# USCI_B0__I2C_Mode_6 register map
Vendor: Texas Instruments
Peripheral module from a debugger description file (folder msp430).
Registers are 16-bit, read-write, reset 0x0 unless marked. A register's access mark holds for its fields unless they carry their own. Offsets are as the file gives them; lines under a group give offsets from that group; [hi:lo] are bit positions; {n}, {i} and the like mark numbered series; 'fields as' and 'values as' point back to an identical list; <NAME> marks a mode.

## USCI_B0_I2C_Mode
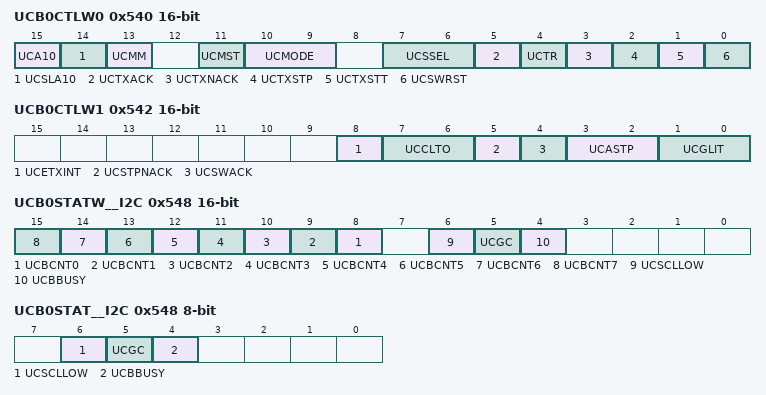
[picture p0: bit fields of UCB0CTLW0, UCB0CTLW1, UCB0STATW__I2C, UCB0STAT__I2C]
0x540 UCB0CTLW0 — USCI B0 Control Word Register 0
  [15] UCA10 — 10-bit Address Mode
  [14] UCSLA10 — 10-bit Slave Address Mode
  [13] UCMM — Multi-Master Environment
  [11] UCMST — Sync. Mode: Master Select
  [10:9] UCMODE — Sync. Mode: USCI Mode 1
    {v}=Sync. Mode: USCI Mode: {v} (v=0..3)
  [7:6] UCSSEL — USCI 1 Clock Source Select 1
    {v}=USCI 0 Clock Source: {v} (v=0..3)
  [5] UCTXACK — Transmit ACK
  [4] UCTR — Transmit/Receive Select/Flag
  [3] UCTXNACK — Transmit NACK
  [2] UCTXSTP — Transmit STOP
  [1] UCTXSTT — Transmit START
  [0] UCSWRST — USCI Software Reset
0x540 UCB0CTL1 8-bit access not given reset not defined — USCI B0 Control Register 1
0x541 UCB0CTL0 8-bit access not given reset not defined — USCI B0 Control Register 0
0x542 UCB0CTLW1 — USCI B0 Control Word Register 1
  [8] UCETXINT — USCI Early UCTXIFG0
  [7:6] UCCLTO — USCI Clock low timeout Bit: 1
    {v}=USCI Clock low timeout: {v} (v=0..3)
  [5] UCSTPNACK — USCI Acknowledge Stop last byte
  [4] UCSWACK — USCI Software controlled ACK
  [3:2] UCASTP — USCI Automatic Stop condition generation Bit: 1
    {v}=USCI Automatic Stop condition generation: {v} (v=0..3)
  [1:0] UCGLIT — USCI Deglitch time Bit: 1
    {v}=USCI Deglitch time: {v} (v=0..3)
0x546 UCB0BRW access not given reset not defined — USCI B0 Baud Word Rate 0
0x546 UCB0BR0 8-bit access not given reset not defined — USCI B0 Baud Rate 0
0x547 UCB0BR1 8-bit access not given reset not defined — USCI B0 Baud Rate 1
0x548 UCB0STATW access not given reset not defined — USCI B0 Status Word Register
0x548 UCB0STATW__I2C — USCI B0 Status Register
  [n+8] UCBCNT{n} (n=0..7) — USCI Byte Counter Bit {n}
  [6] UCSCLLOW — SCL low
  [5] UCGC — General Call address received Flag
  [4] UCBBUSY — Bus Busy Flag
0x548 UCB0STAT__I2C 8-bit — USCI B0 Status Register
  [6] UCSCLLOW — SCL low
  [5] UCGC — General Call address received Flag
  [4] UCBBUSY — Bus Busy Flag
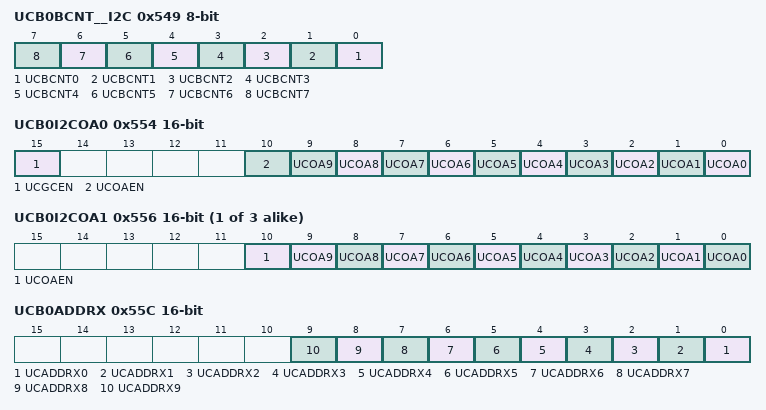
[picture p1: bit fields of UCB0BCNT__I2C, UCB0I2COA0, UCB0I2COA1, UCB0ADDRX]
0x549 UCB0BCNT__I2C 8-bit — USCI B0 Byte Counter Register
  [n] UCBCNT{n} (n=0..7) — USCI Byte Counter Bit {n}
0x54A UCB0TBCNT access not given reset not defined — USCI B0 Byte Counter Threshold Register
0x54C UCB0RXBUF access not given reset not defined — USCI B0 Receive Buffer
0x54E UCB0TXBUF access not given reset not defined — USCI B0 Transmit Buffer
0x554 UCB0I2COA0 — USCI B0 I2C Own Address 0
  [15] UCGCEN — I2C General Call enable
  [10] UCOAEN — I2C Own Address enable
  [n] UCOA{n} (n=0..9) — I2C Own Address Bit {n}
{0x554+2i} UCB0I2COA{i} (i=1..3) — USCI B0 I2C Own Address {i}
  [10] UCOAEN — I2C Own Address enable
  [n] UCOA{n} (n=0..9) — I2C Own Address Bit {n}
0x55C UCB0ADDRX — USCI B0 Received Address Register
  [n] UCADDRX{n} (n=0..9) — I2C Receive Address Bit {n}
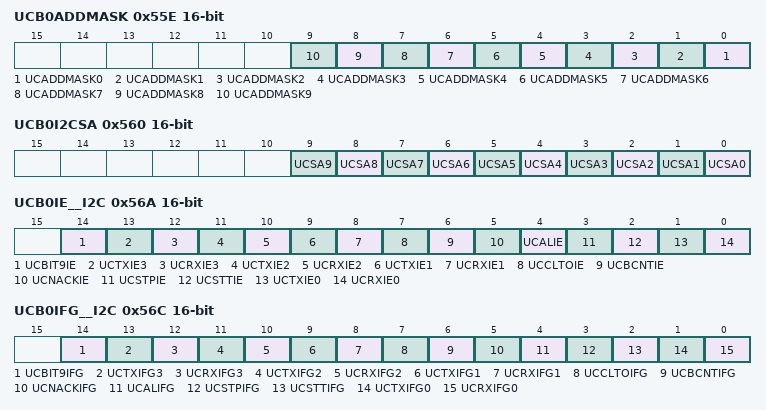
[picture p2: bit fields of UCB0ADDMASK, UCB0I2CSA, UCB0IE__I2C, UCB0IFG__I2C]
0x55E UCB0ADDMASK — USCI B0 Address Mask Register
  [n] UCADDMASK{n} (n=0..9) — I2C Address Mask Bit {n}
0x560 UCB0I2CSA — USCI B0 I2C Slave Address
  [n] UCSA{n} (n=0..9) — I2C Slave Address Bit {n}
0x56A UCB0IE access not given reset not defined — USCI B0 Interrupt Enable Register
0x56A UCB0IE__I2C — USCI B0 Interrupt Enable Register
  [14] UCBIT9IE — I2C Bit 9 Position Interrupt Enable 3
  [13] UCTXIE3 — I2C Transmit Interrupt Enable 3
  [12] UCRXIE3 — I2C Receive Interrupt Enable 3
  [11] UCTXIE2 — I2C Transmit Interrupt Enable 2
  [10] UCRXIE2 — I2C Receive Interrupt Enable 2
  [9] UCTXIE1 — I2C Transmit Interrupt Enable 1
  [8] UCRXIE1 — I2C Receive Interrupt Enable 1
  [7] UCCLTOIE — I2C Clock Low Timeout interrupt enable
  [6] UCBCNTIE — I2C Automatic stop assertion interrupt enable
  [5] UCNACKIE — I2C NACK Condition interrupt enable
  [4] UCALIE — I2C Arbitration Lost interrupt enable
  [3] UCSTPIE — I2C STOP Condition interrupt enable
  [2] UCSTTIE — I2C START Condition interrupt enable
  [1] UCTXIE0 — I2C Transmit Interrupt Enable 0
  [0] UCRXIE0 — I2C Receive Interrupt Enable 0
0x56C UCB0IFG access not given reset not defined — USCI B0 Interrupt Flags Register
0x56C UCB0IFG__I2C — USCI B0 Interrupt Flags Register
  [14] UCBIT9IFG — I2C Bit 9 Possition Interrupt Flag 3
  [13] UCTXIFG3 — I2C Transmit Interrupt Flag 3
  [12] UCRXIFG3 — I2C Receive Interrupt Flag 3
  [11] UCTXIFG2 — I2C Transmit Interrupt Flag 2
  [10] UCRXIFG2 — I2C Receive Interrupt Flag 2
  [9] UCTXIFG1 — I2C Transmit Interrupt Flag 1
  [8] UCRXIFG1 — I2C Receive Interrupt Flag 1
  [7] UCCLTOIFG — I2C Clock low Timeout interrupt Flag
  [6] UCBCNTIFG — I2C Byte counter interrupt flag
  [5] UCNACKIFG — I2C NACK Condition interrupt Flag
  [4] UCALIFG — I2C Arbitration Lost interrupt Flag
  [3] UCSTPIFG — I2C STOP Condition interrupt Flag
  [2] UCSTTIFG — I2C START Condition interrupt Flag
  [1] UCTXIFG0 — I2C Transmit Interrupt Flag 0
  [0] UCRXIFG0 — I2C Receive Interrupt Flag 0
0x56E UCB0IV access not given reset not defined — USCI B0 Interrupt Vector Register
